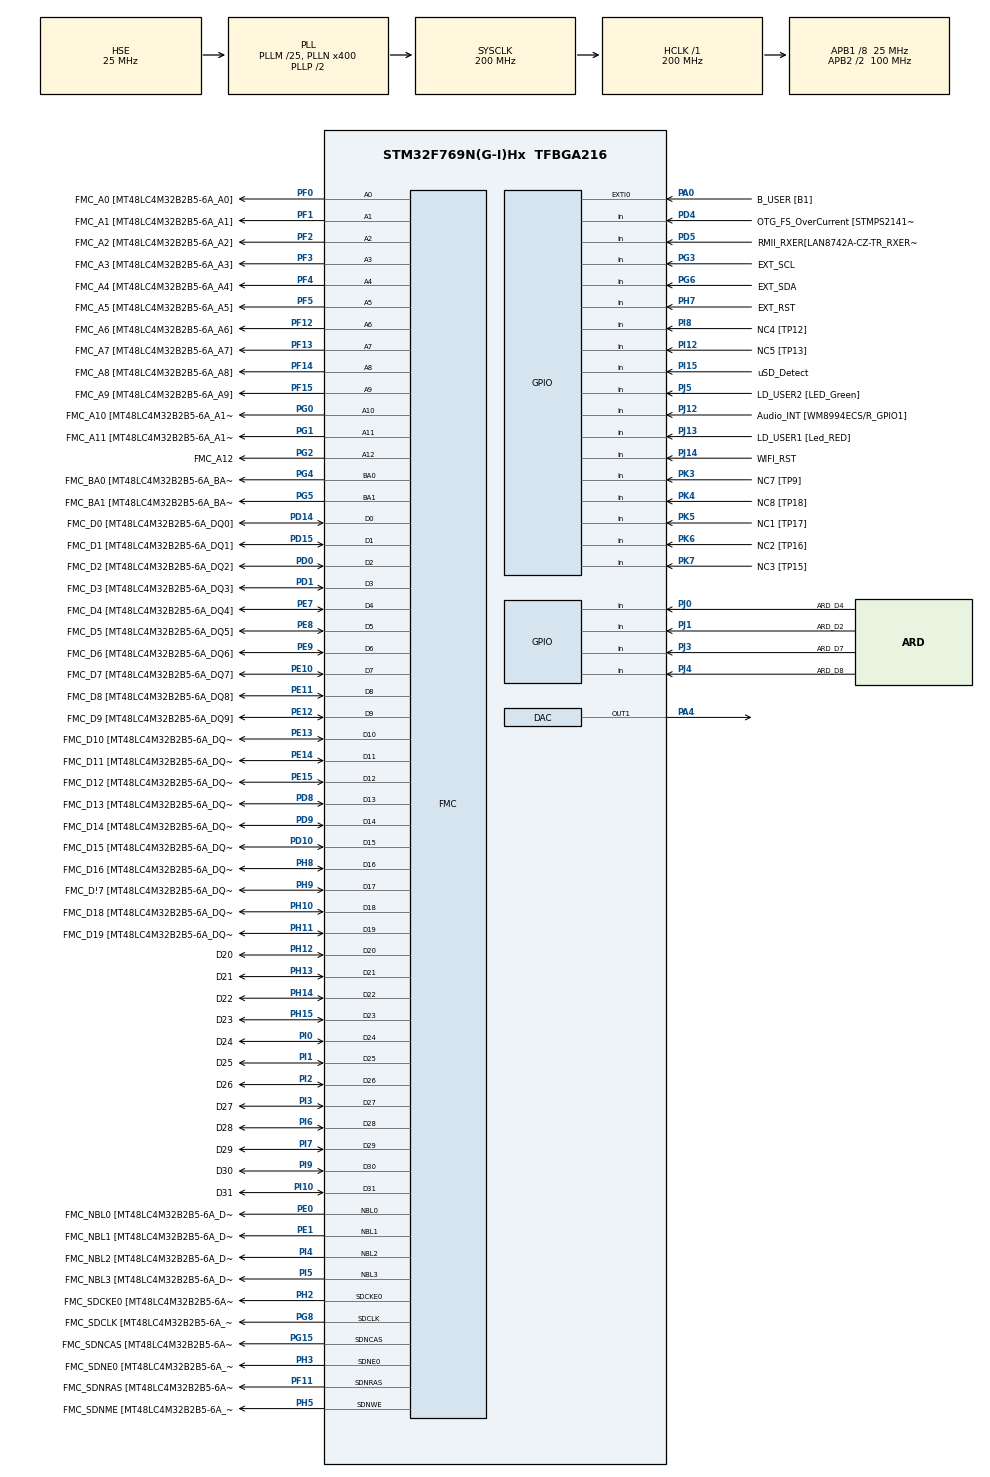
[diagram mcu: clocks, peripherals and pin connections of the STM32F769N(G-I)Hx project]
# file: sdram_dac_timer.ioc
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DAC.DAC_Channel=DAC_CHANNEL_1
DAC.DAC_OutputBuffer=DAC_OUTPUTBUFFER_ENABLE
DAC.DAC_Trigger=DAC_TRIGGER_T6_TRGO
DAC.WaveGeneration=DISABLE
Dma.DAC1.1.Direction=DMA_MEMORY_TO_PERIPH
Dma.DAC1.1.FIFOMode=DMA_FIFOMODE_DISABLE
Dma.DAC1.1.Instance=DMA1_Stream5
Dma.DAC1.1.MemDataAlignment=DMA_MDATAALIGN_HALFWORD
Dma.DAC1.1.MemInc=DMA_MINC_ENABLE
Dma.DAC1.1.Mode=DMA_CIRCULAR
Dma.DAC1.1.PeriphDataAlignment=DMA_PDATAALIGN_HALFWORD
Dma.DAC1.1.PeriphInc=DMA_PINC_DISABLE
Dma.DAC1.1.Priority=DMA_PRIORITY_LOW
Dma.MEMTOMEM.0.Direction=DMA_MEMORY_TO_MEMORY
Dma.MEMTOMEM.0.FIFOMode=DMA_FIFOMODE_ENABLE
Dma.MEMTOMEM.0.FIFOThreshold=DMA_FIFO_THRESHOLD_FULL
Dma.MEMTOMEM.0.Instance=DMA2_Stream0
Dma.MEMTOMEM.0.MemBurst=DMA_MBURST_SINGLE
Dma.MEMTOMEM.0.MemDataAlignment=DMA_MDATAALIGN_BYTE
Dma.MEMTOMEM.0.MemInc=DMA_MINC_ENABLE
Dma.MEMTOMEM.0.Mode=DMA_NORMAL
Dma.MEMTOMEM.0.PeriphBurst=DMA_PBURST_SINGLE
Dma.MEMTOMEM.0.PeriphDataAlignment=DMA_PDATAALIGN_BYTE
Dma.MEMTOMEM.0.PeriphInc=DMA_PINC_ENABLE
Dma.MEMTOMEM.0.Priority=DMA_PRIORITY_LOW
Dma.Request0=MEMTOMEM
Dma.Request1=DAC1
FMC.CASLatency1=FMC_SDRAM_CAS_LATENCY_2
FMC.ExitSelfRefreshDelay1=7
FMC.InternalBankNumber1=FMC_SDRAM_INTERN_BANKS_NUM_4
FMC.LoadToActiveDelay1=2
FMC.RCDDelay1=2
FMC.RPDelay1=2
FMC.RPDelay2=2
FMC.ReadBurst1=FMC_SDRAM_RBURST_ENABLE
FMC.ReadBurst2=FMC_SDRAM_RBURST_ENABLE
FMC.RowCycleDelay1=6
FMC.RowCycleDelay2=6
FMC.SDClockPeriod1=FMC_SDRAM_CLOCK_PERIOD_2
FMC.SDClockPeriod2=FMC_SDRAM_CLOCK_PERIOD_2
FMC.SDCoherentPinout1=MEMORY_PINOUT_OK
FMC.SDMemoryDataWidth1=FMC_SDRAM_MEM_BUS_WIDTH_32
FMC.SDRAM_Instance=FMC_SDRAM_DEVICE
FMC.SelfRefreshTime1=4
FMC.WriteRecoveryTime1=2
Mcu.Family=STM32F7
Mcu.Name=STM32F769N(G-I)Hx
Mcu.Package=TFBGA216
NVIC.DMA1_Stream5_IRQn=true\:0\:0\:false\:false\:true
NVIC.PriorityGroup=NVIC_PRIORITYGROUP_4
PA0/WKUP.GPIO_Label=B_USER [B1]
PA0/WKUP.Signal=GPXTI0
PA1.GPIO_Label=RMII_REF_CLK [LAN8742A-CZ-TR_REFCLK0]
PA1.Signal=ETH_REF_CLK
PA10.GPIO_Label=VCP_RX 
PA10.Signal=USART1_RX
PA11.GPIO_Label=SPI2_NSS
PA11.Signal=SPI2_NSS
PA12.GPIO_Label=ARD_D13/SCK
PA12.GPIO_Mode=GPIO_MODE_AF_PP
PA12.GPIO_PuPd=GPIO_NOPULL
PA12.GPIO_Speed=GPIO_SPEED_FREQ_LOW
PA12.Signal=SPI2_SCK
PA13.GPIO_Label=SWDIO
PA13.Signal=SYS_JTMS-SWDIO
PA14.GPIO_Label=SWCLK
PA14.Signal=SYS_JTCK-SWCLK
PA2.GPIO_Label=RMII_MDIO [LAN8742A-CZ-TR_MDIO]
PA2.Signal=ETH_MDIO
PA3.GPIO_Label=ULPI_D0 [USB3320C-EZK_D0]
PA3.Signal=USB_OTG_HS_ULPI_D0
PA4.Signal=COMP_DAC1_group
PA5.GPIO_Label=ULPI_CLK [USB3320C-EZK_CLKOUT]
PA5.Signal=USB_OTG_HS_ULPI_CK
PA6.GPIO_Label=ARD_A0
PA6.Signal=ADCx_IN6
PA7.GPIO_Label=RMII_CRS_DV [LAN8742A-CZ-TR_CRS_DV]
PA7.Signal=ETH_CRS_DV
PA9.GPIO_Label=VCP_TX [STM32F103CBT6_PA3]
PA9.GPIO_Mode=GPIO_MODE_AF_PP
PA9.GPIO_PuPd=GPIO_NOPULL
PA9.GPIO_Speed=GPIO_SPEED_FREQ_LOW
PA9.Signal=USART1_TX
PB0.GPIO_Label=ULPI_D1 [USB3320C-EZK_D1]
PB0.Signal=USB_OTG_HS_ULPI_D1
PB1.GPIO_Label=ULPI_D2 [USB3320C-EZK_D2]
PB1.Signal=USB_OTG_HS_ULPI_D2
PB10.GPIO_Label=ULPI_D3 [USB3320C-EZK_D3]
PB10.Signal=USB_OTG_HS_ULPI_D3
PB11.GPIO_Label=ULPI_D4 [USB3320C-EZK_D4]
PB11.Signal=USB_OTG_HS_ULPI_D4
PB12.GPIO_Label=ULPI_D5 [USB3320C-EZK_D5]
PB12.Signal=USB_OTG_HS_ULPI_D5
PB13.GPIO_Label=ULPI_D6 [USB3320C-EZK_D6]
PB13.Signal=USB_OTG_HS_ULPI_D6
PB14.GPIO_Label=ARDUINO MISO/D12
PB14.GPIO_Mode=GPIO_MODE_AF_PP
PB14.GPIO_PuPd=GPIO_NOPULL
PB14.GPIO_Speed=GPIO_SPEED_FREQ_LOW
PB14.Signal=SPI2_MISO
PB15.GPIO_Label=ARDUINO MOSI/PWM/D11
PB15.GPIO_Mode=GPIO_MODE_AF_PP
PB15.GPIO_PuPd=GPIO_NOPULL
PB15.GPIO_Speed=GPIO_SPEED_FREQ_LOW
PB15.Signal=SPI2_MOSI
PB2.GPIO_Label=QSPI_CLK
PB2.Signal=QUADSPI_CLK
PB3.GPIO_Label=uSD_D2
PB3.Signal=SDMMC2_D2
PB4.GPIO_Label=uSD_D3
PB4.Signal=SDMMC2_D3
PB5.GPIO_Label=ULPI_D7 [USB3320C-EZK_D7]
PB5.Signal=USB_OTG_HS_ULPI_D7
PB6.GPIO_Label=QSPI_NCS [N25Q128A13EF840E_S]
PB6.Signal=QUADSPI_BK1_NCS
PB7.GPIO_Label=AUDIO_SDA [WM8994ECS/R_SDA]
PB7.Signal=I2C4_SDA
PB8.GPIO_Label=ARDUINO SCL/D15
PB8.GPIO_Mode=GPIO_MODE_AF_OD
PB8.GPIO_PuPd=GPIO_NOPULL
PB8.GPIO_Speed=GPIO_SPEED_FREQ_LOW
PB8.Signal=I2C1_SCL
PB9.GPIO_Label=ARDUINO SDA/D14
PB9.GPIO_Mode=GPIO_MODE_AF_OD
PB9.GPIO_PuPd=GPIO_NOPULL
PB9.GPIO_Speed=GPIO_SPEED_FREQ_LOW
PB9.Signal=I2C1_SDA
PC0.GPIO_Label=ULPI_STP [USB3320C-EZK_STP]
PC0.Signal=USB_OTG_HS_ULPI_STP
PC1.GPIO_Label=RMII_MDC [LAN8742A-CZ-TR_MDC]
PC1.Signal=ETH_MDC
PC10.GPIO_Label=QSPI_D1 [MT25QL512ABB1EW9_DQ1]
PC10.Signal=QUADSPI_BK1_IO1
PC11.GPIO_Label=DFSDM_DATIN5 [TP100]
PC11.Signal=S_DATAIN5DFSDM1
PC12.GPIO_Label=WIFI_RX
PC12.Signal=UART5_TX
PC13.Signal=RTC_OUT_ALARM
PC14/OSC32_IN.GPIO_Label=RCC_OSC32_IN
PC14/OSC32_IN.Signal=RCC_OSC32_IN
PC15/OSC32_OUT.GPIO_Label=RCC_OSC32_OUT
PC15/OSC32_OUT.Signal=RCC_OSC32_OUT
PC2.GPIO_Label=ARD_A2
PC2.Signal=ADCx_IN12
PC3.GPIO_Label=DFSDM_DATIN1 [TP101]
PC3.Signal=S_DATAIN1DFSDM1
PC4.GPIO_Label=RMII_RXD0 [LAN8742A-CZ-TR_RXD0]
PC4.Signal=ETH_RXD0
PC5.GPIO_Label=RMII_RXD1 [LAN8742A-CZ-TR_RXD1]
PC5.Signal=ETH_RXD1
PC6.GPIO_Label=ARDUINO TX/D1
PC6.Signal=USART6_TX
PC7.GPIO_Label=ARD_D0/RX
PC7.Signal=USART6_RX
PC8.GPIO_Label=ARD_D5/PWM
PC8.Signal=S_TIM3_CH3
PC9.GPIO_Label=QSPI_D0 [N25Q128A13EF840E_DQ0]
PC9.Signal=QUADSPI_BK1_IO0
PD0.GPIO_Label=FMC_D2 [MT48LC4M32B2B5-6A_DQ2]
PD0.Signal=FMC_D2_DA2
PD1.GPIO_Label=FMC_D3 [MT48LC4M32B2B5-6A_DQ3]
PD1.Signal=FMC_D3_DA3
PD10.GPIO_Label=FMC_D15 [MT48LC4M32B2B5-6A_DQ15]
PD10.Signal=FMC_D15_DA15
PD11.GPIO_Label=SPDIF_TX [TP20]
PD11.Signal=SAI2_SD_A
PD12.GPIO_Label=AUDIO_SCL [WM8994ECS/R_SCLK]
PD12.Signal=I2C4_SCL
PD13.GPIO_Label=QSPI_D3 [N25Q128A13EF840E_DQ3]
PD13.Signal=QUADSPI_BK1_IO3
PD14.GPIO_Label=FMC_D0 [MT48LC4M32B2B5-6A_DQ0]
PD14.Signal=FMC_D0_DA0
PD15.GPIO_Label=FMC_D1 [MT48LC4M32B2B5-6A_DQ1]
PD15.Signal=FMC_D1_DA1
PD2.GPIO_Label=WIFI_TX
PD2.Signal=UART5_RX
PD3.GPIO_Label=DFSDM_CKOUT [TP102]
PD3.Signal=S_CKOUTDFSDM1
PD4.GPIO_Label=OTG_FS_OverCurrent [STMPS2141STR_Fault]
PD4.Signal=GPIO_Input
PD5.GPIO_Label=RMII_RXER[LAN8742A-CZ-TR_RXERR]
PD5.Signal=GPIO_Input
PD6.GPIO_Label=uSD_CLK
PD6.Signal=SDMMC2_CK
PD7.GPIO_Label=uSD_CMD
PD7.Signal=SDMMC2_CMD
PD8.GPIO_Label=FMC_D13 [MT48LC4M32B2B5-6A_DQ13]
PD8.Signal=FMC_D13_DA13
PD9.GPIO_Label=FMC_D14 [MT48LC4M32B2B5-6A_DQ14]
PD9.Signal=FMC_D14_DA14
PE0.GPIO_Label=FMC_NBL0 [MT48LC4M32B2B5-6A_DQM0]
PE0.Signal=FMC_NBL0
PE1.GPIO_Label=FMC_NBL1 [MT48LC4M32B2B5-6A_DQM1]
PE1.Signal=FMC_NBL1
PE10.GPIO_Label=FMC_D7 [MT48LC4M32B2B5-6A_DQ7]
PE10.Signal=FMC_D7_DA7
PE11.GPIO_Label=FMC_D8 [MT48LC4M32B2B5-6A_DQ8]
PE11.Signal=FMC_D8_DA8
PE12.GPIO_Label=FMC_D9 [MT48LC4M32B2B5-6A_DQ9]
PE12.Signal=FMC_D9_DA9
PE13.GPIO_Label=FMC_D10 [MT48LC4M32B2B5-6A_DQ10]
PE13.Signal=FMC_D10_DA10
PE14.GPIO_Label=FMC_D11 [MT48LC4M32B2B5-6A_DQ11]
PE14.Signal=FMC_D11_DA11
PE15.GPIO_Label=FMC_D12 [MT48LC4M32B2B5-6A_DQ12]
PE15.Signal=FMC_D12_DA12
PE2.GPIO_Label=QSPI_D2 [N25Q128A13EF840E_DQ2]
PE2.Signal=QUADSPI_BK1_IO2
PE3.GPIO_Label=SAI1_SDB [WM8994ECS/R_ADCDAT1]
PE3.Signal=SAI1_SD_B
PE4.GPIO_Label=SAI1_FSA [WM8994ECS/R_LRCLK1]
PE4.Signal=SAI1_FS_A
PE5.GPIO_Label=SAI1_SCKA [WM8994ECS/R_BCLK1]
PE5.Signal=SAI1_SCK_A
PE6.GPIO_Label=SAI1_SDA [WM8994ECS/R_DACDAT1]
PE6.Signal=SAI1_SD_A
PE7.GPIO_Label=FMC_D4 [MT48LC4M32B2B5-6A_DQ4]
PE7.Signal=FMC_D4_DA4
PE8.GPIO_Label=FMC_D5 [MT48LC4M32B2B5-6A_DQ5]
PE8.Signal=FMC_D5_DA5
PE9.GPIO_Label=FMC_D6 [MT48LC4M32B2B5-6A_DQ6]
PE9.Signal=FMC_D6_DA6
PF0.GPIO_Label=FMC_A0 [MT48LC4M32B2B5-6A_A0]
PF0.Signal=FMC_A0
PF1.GPIO_Label=FMC_A1 [MT48LC4M32B2B5-6A_A1]
PF1.Signal=FMC_A1
PF10.GPIO_Label=ARDUINO A1
PF10.GPIO_Mode=GPIO_MODE_ANALOG
PF10.GPIO_PuPd=GPIO_NOPULL
PF10.Signal=ADC3_IN8
PF11.GPIO_Label=FMC_SDNRAS [MT48LC4M32B2B5-6A_RAS]
PF11.Signal=FMC_SDNRAS
PF12.GPIO_Label=FMC_A6 [MT48LC4M32B2B5-6A_A6]
PF12.Signal=FMC_A6
PF13.GPIO_Label=FMC_A7 [MT48LC4M32B2B5-6A_A7]
PF13.Signal=FMC_A7
PF14.GPIO_Label=FMC_A8 [MT48LC4M32B2B5-6A_A8]
PF14.Signal=FMC_A8
PF15.GPIO_Label=FMC_A9 [MT48LC4M32B2B5-6A_A9]
PF15.Signal=FMC_A9
PF2.GPIO_Label=FMC_A2 [MT48LC4M32B2B5-6A_A2]
PF2.Signal=FMC_A2
PF3.GPIO_Label=FMC_A3 [MT48LC4M32B2B5-6A_A3]
PF3.Signal=FMC_A3
PF4.GPIO_Label=FMC_A4 [MT48LC4M32B2B5-6A_A4]
PF4.Signal=FMC_A4
PF5.GPIO_Label=FMC_A5 [MT48LC4M32B2B5-6A_A5]
PF5.Signal=FMC_A5
PF6.GPIO_Label=ARD_D3/PWM
PF6.Signal=S_TIM10_CH1
PF7.GPIO_Label=ARD_D6/PWM
PF7.Signal=S_TIM11_CH1
PF8.GPIO_Label=ARDUINO A3
PF8.GPIO_Mode=GPIO_MODE_ANALOG
PF8.GPIO_PuPd=GPIO_NOPULL
PF8.Signal=ADC3_IN6
PF9.GPIO_Label=ARDUINO A2
PF9.GPIO_Mode=GPIO_MODE_ANALOG
PF9.GPIO_PuPd=GPIO_NOPULL
PF9.Signal=ADC3_IN7
PG0.GPIO_Label=FMC_A10 [MT48LC4M32B2B5-6A_A10]
PG0.Signal=FMC_A10
PG1.GPIO_Label=FMC_A11 [MT48LC4M32B2B5-6A_A11]
PG1.Signal=FMC_A11
PG10.GPIO_Label=uSD_D1
PG10.Signal=SDMMC2_D1
PG11.GPIO_Label=RMII_TX_EN [LAN8742A-CZ-TR_TXEN]
PG11.Signal=ETH_TX_EN
PG12.GPIO_Label=SPDIF_RX [74LVC1G04SE_4]
PG12.Signal=SPDIFRX_IN1
PG13.GPIO_Label=RMII_TXD0 [LAN8742A-CZ-TR_TXD0]
PG13.Signal=ETH_TXD0
PG14.GPIO_Label=RMII_TXD1 [LAN8742A-CZ-TR_TXD1]
PG14.Signal=ETH_TXD1
PG15.GPIO_Label=FMC_SDNCAS [MT48LC4M32B2B5-6A_CAS]
PG15.Signal=FMC_SDNCAS
PG2.GPIO_Label=FMC_A12
PG2.Signal=FMC_A12
PG3.GPIO_Label=EXT_SCL
PG3.Signal=GPIO_Input
PG4.GPIO_Label=FMC_BA0 [MT48LC4M32B2B5-6A_BA0]
PG4.Signal=FMC_A14_BA0
PG5.GPIO_Label=FMC_BA1 [MT48LC4M32B2B5-6A_BA1]
PG5.Signal=FMC_A15_BA1
PG6.GPIO_Label=EXT_SDA
PG6.Signal=GPIO_Input
PG7.GPIO_Label=SAI1_MCLKA [WM8994ECS/R_MCLK1]
PG7.Signal=SAI1_MCLK_A
PG8.GPIO_Label=FMC_SDCLK [MT48LC4M32B2B5-6A_CLK]
PG8.Signal=FMC_SDCLK
PG9.GPIO_Label=uSD_D0
PG9.Signal=SDMMC2_D0
PH0/OSC_IN.GPIO_Label=OSC_25M [NZ2520SB-25.00M_OUT]
PH0/OSC_IN.Mode=HSE-External-Clock-Source
PH0/OSC_IN.Signal=RCC_OSC_IN
PH1/OSC_OUT.Mode=HSE-External-Clock-Source
PH1/OSC_OUT.Signal=RCC_OSC_OUT
PH10.GPIO_Label=FMC_D18 [MT48LC4M32B2B5-6A_DQ18]
PH10.Signal=FMC_D18
PH11.GPIO_Label=FMC_D19 [MT48LC4M32B2B5-6A_DQ19]
PH11.Signal=FMC_D19
PH12.GPIO_Label=D20
PH12.Signal=FMC_D20
PH13.GPIO_Label=D21
PH13.Signal=FMC_D21
PH14.GPIO_Label=D22
PH14.Signal=FMC_D22
PH15.GPIO_Label=D23
PH15.Signal=FMC_D23
PH2.GPIO_Label=FMC_SDCKE0 [MT48LC4M32B2B5-6A_CKE]
PH2.Mode=SdramChipSelect1_1
PH2.Signal=FMC_SDCKE0
PH3.GPIO_Label=FMC_SDNE0 [MT48LC4M32B2B5-6A_CS]
PH3.Mode=SdramChipSelect1_1
PH3.Signal=FMC_SDNE0
PH4.GPIO_Label=ULPI_NXT [USB3320C-EZK_NXT]
PH4.Signal=USB_OTG_HS_ULPI_NXT
PH5.GPIO_Label=FMC_SDNME [MT48LC4M32B2B5-6A_WE]
PH5.Signal=FMC_SDNWE
PH6.GPIO_Label=ARDUINO PWM/D6
PH6.Signal=S_TIM12_CH1
PH7.GPIO_Label=EXT_RST
PH7.Signal=GPIO_Input
PH8.GPIO_Label=FMC_D16 [MT48LC4M32B2B5-6A_DQ16]
PH8.Signal=FMC_D16
PH9.GPIO_Label=FMC_D\!7 [MT48LC4M32B2B5-6A_DQ17]
PH9.Signal=FMC_D17
PI0.GPIO_Label=D24
PI0.Signal=FMC_D24
PI1.GPIO_Label=D25
PI1.Signal=FMC_D25
PI10.GPIO_Label=D31
PI10.Signal=FMC_D31
PI11.GPIO_Label=ULPI_DIR [USB3320C-EZK_DIR]
PI11.Signal=USB_OTG_HS_ULPI_DIR
PI12.GPIO_Label=NC5 [TP13]
PI12.Signal=GPIO_Input
PI15.GPIO_Label=uSD_Detect
PI15.Signal=GPIO_Input
PI2.GPIO_Label=D26
PI2.Signal=FMC_D26
PI3.GPIO_Label=D27
PI3.Signal=FMC_D27
PI4.GPIO_Label=FMC_NBL2 [MT48LC4M32B2B5-6A_DQM2]
PI4.Signal=FMC_NBL2
PI5.GPIO_Label=FMC_NBL3 [MT48LC4M32B2B5-6A_DQM3]
PI5.Signal=FMC_NBL3
PI6.GPIO_Label=D28
PI6.Signal=FMC_D28
PI7.GPIO_Label=D29
PI7.Signal=FMC_D29
PI8.GPIO_Label=NC4 [TP12]
PI8.Signal=GPIO_Input
PI9.GPIO_Label=D30
PI9.Signal=FMC_D30
PJ0.GPIO_Label=ARD_D4
PJ0.Signal=GPIO_Input
PJ1.GPIO_Label=ARD_D2
PJ1.Signal=GPIO_Input
PJ12.GPIO_Label=Audio_INT [WM8994ECS/R_GPIO1]
PJ12.Signal=GPIO_Input
PJ13.GPIO_Label=LD_USER1 [Led_RED]
PJ13.Signal=GPIO_Input
PJ14.GPIO_Label=WIFI_RST
PJ14.Signal=GPIO_Input
PJ3.GPIO_Label=ARD_D7
PJ3.Signal=GPIO_Input
PJ4.GPIO_Label=ARD_D8
PJ4.Signal=GPIO_Input
PJ5.GPIO_Label=LD_USER2 [LED_Green]
PJ5.Signal=GPIO_Input
PK3.GPIO_Label=NC7 [TP9]
PK3.Signal=GPIO_Input
PK4.GPIO_Label=NC8 [TP18]
PK4.Signal=GPIO_Input
PK5.GPIO_Label=NC1 [TP17]
PK5.Signal=GPIO_Input
PK6.GPIO_Label=NC2 [TP16]
PK6.Signal=GPIO_Input
PK7.GPIO_Label=NC3 [TP15]
PK7.Signal=GPIO_Input
ProjectManager.HeapSize=0x200
ProjectManager.StackSize=0x400
ProjectManager.TargetToolchain=MDK-ARM V5
RCC.AHBCLKDivider=RCC_SYSCLK_DIV1
RCC.AHBFreq_Value=200000000
RCC.APB1CLKDivider=RCC_HCLK_DIV8
RCC.APB1Freq_Value=25000000
RCC.APB1TimFreq_Value=50000000
RCC.APB2CLKDivider=RCC_HCLK_DIV2
RCC.APB2Freq_Value=100000000
RCC.APB2TimFreq_Value=200000000
RCC.CECEnable=false
RCC.ClockTypeHCLK=RCC_CLOCKTYPE_HCLK
RCC.ClockTypePCLK1=RCC_CLOCKTYPE_PCLK1
RCC.ClockTypePCLK2=RCC_CLOCKTYPE_PCLK2
RCC.ClockTypeSysClk=RCC_CLOCKTYPE_SYSCLK
RCC.CortexFreq_Value=200000000
RCC.EnableHSE=true
RCC.EnableHSERTCDevisor=false
RCC.EnableLSE=false
RCC.EnableLSERTC=false
RCC.EnbaleCSS=false
RCC.ExtClockEnable=false
RCC.HCLKFreq_Value=200000000
RCC.HSEState=RCC_HSE_BYPASS
RCC.HSE_VALUE=25000000
RCC.HSIState=RCC_HSI_ON
RCC.HSI_VALUE=16000000
RCC.I2C1Enable=false
RCC.I2C2Enable=false
RCC.I2C3Enable=false
RCC.I2C4Enable=false
RCC.I2SEnable=false
RCC.LCDEnable=false
RCC.LPTIM1Enable=false
RCC.LSE_VALUE=32768
RCC.LSIState=RCC_LSI_OFF
RCC.MCO1OutPutEnable=false
RCC.MCO2I2SEnable=false
RCC.MCO2OutPutEnable=false
RCC.OscillatorTypeHSE=RCC_OSCILLATORTYPE_HSE
RCC.OscillatorTypeHSI=RCC_OSCILLATORTYPE_HSI
RCC.PLLM=25
RCC.PLLN=400
RCC.PLLP=RCC_PLLP_DIV2
RCC.PLLQ=4
RCC.PLLSAIQ=3
RCC.PLLSourceVirtual=RCC_PLLSOURCE_HSE
RCC.PLLState=RCC_PLL_ON
RCC.RTCEnable=false
RCC.SAI1Enable=false
RCC.SAI2Enable=false
RCC.SDMMC1Enable=false
RCC.SPDIFEnable=false
RCC.SYSCLKFreq_VALUE=200000000
RCC.SYSCLKSource=RCC_SYSCLKSOURCE_PLLCLK
RCC.UART4Enable=false
RCC.UART5Enable=false
RCC.UART7Enable=false
RCC.UART8Enable=false
RCC.USART1Enable=false
RCC.USART2Enable=false
RCC.USART3Enable=false
RCC.USART6Enable=false
RCC.USBEnable=false
RCC.USBFreq_Value=100000000
RCC.VCOOutputFreq_Value=400000000
SH.ADCx_IN12.0=ADC1_IN12
SH.ADCx_IN6.0=ADC1_IN6
SH.COMP_DAC1_group.0=DAC_OUT1,DAC_OUT1
SH.FMC_A0.0=FMC_A0,13b-sda1
SH.FMC_A1.0=FMC_A1,13b-sda1
SH.FMC_A10.0=FMC_A10,13b-sda1
SH.FMC_A11.0=FMC_A11,13b-sda1
SH.FMC_A12.0=FMC_A12,13b-sda1
SH.FMC_A14_BA0.0=FMC_BA0,FourSdramBanks1
SH.FMC_A15_BA1.0=FMC_BA1,FourSdramBanks1
SH.FMC_A2.0=FMC_A2,13b-sda1
SH.FMC_A3.0=FMC_A3,13b-sda1
SH.FMC_A4.0=FMC_A4,13b-sda1
SH.FMC_A5.0=FMC_A5,13b-sda1
SH.FMC_A6.0=FMC_A6,13b-sda1
SH.FMC_A7.0=FMC_A7,13b-sda1
SH.FMC_A8.0=FMC_A8,13b-sda1
SH.FMC_A9.0=FMC_A9,13b-sda1
SH.FMC_D0_DA0.0=FMC_D0,sd-32b-d1
SH.FMC_D10_DA10.0=FMC_D10,sd-32b-d1
SH.FMC_D11_DA11.0=FMC_D11,sd-32b-d1
SH.FMC_D12_DA12.0=FMC_D12,sd-32b-d1
SH.FMC_D13_DA13.0=FMC_D13,sd-32b-d1
SH.FMC_D14_DA14.0=FMC_D14,sd-32b-d1
SH.FMC_D15_DA15.0=FMC_D15,sd-32b-d1
SH.FMC_D16.0=FMC_D16,sd-32b-d1
SH.FMC_D17.0=FMC_D17,sd-32b-d1
SH.FMC_D18.0=FMC_D18,sd-32b-d1
SH.FMC_D19.0=FMC_D19,sd-32b-d1
SH.FMC_D1_DA1.0=FMC_D1,sd-32b-d1
SH.FMC_D20.0=FMC_D20,sd-32b-d1
SH.FMC_D21.0=FMC_D21,sd-32b-d1
SH.FMC_D22.0=FMC_D22,sd-32b-d1
SH.FMC_D23.0=FMC_D23,sd-32b-d1
SH.FMC_D24.0=FMC_D24,sd-32b-d1
SH.FMC_D25.0=FMC_D25,sd-32b-d1
SH.FMC_D26.0=FMC_D26,sd-32b-d1
SH.FMC_D27.0=FMC_D27,sd-32b-d1
SH.FMC_D28.0=FMC_D28,sd-32b-d1
SH.FMC_D29.0=FMC_D29,sd-32b-d1
SH.FMC_D2_DA2.0=FMC_D2,sd-32b-d1
SH.FMC_D30.0=FMC_D30,sd-32b-d1
SH.FMC_D31.0=FMC_D31,sd-32b-d1
SH.FMC_D3_DA3.0=FMC_D3,sd-32b-d1
SH.FMC_D4_DA4.0=FMC_D4,sd-32b-d1
SH.FMC_D5_DA5.0=FMC_D5,sd-32b-d1
SH.FMC_D6_DA6.0=FMC_D6,sd-32b-d1
SH.FMC_D7_DA7.0=FMC_D7,sd-32b-d1
SH.FMC_D8_DA8.0=FMC_D8,sd-32b-d1
SH.FMC_D9_DA9.0=FMC_D9,sd-32b-d1
SH.FMC_NBL0.0=FMC_NBL0,Sd4ByteEnable1
SH.FMC_NBL1.0=FMC_NBL1,Sd4ByteEnable1
SH.FMC_NBL2.0=FMC_NBL2,Sd4ByteEnable1
SH.FMC_NBL3.0=FMC_NBL3,Sd4ByteEnable1
SH.FMC_SDCLK.0=FMC_SDCLK,13b-sda1
SH.FMC_SDNCAS.0=FMC_SDNCAS,13b-sda1
SH.FMC_SDNRAS.0=FMC_SDNRAS,13b-sda1
SH.FMC_SDNWE.0=FMC_SDNWE,13b-sda1
SH.S_CKOUTDFSDM1.0=DFSDM1_CKOUT
SH.S_DATAIN1DFSDM1.0=DFSDM1_DATIN1
SH.S_DATAIN5DFSDM1.0=DFSDM1_DATIN5
SH.S_TIM10_CH1.0=TIM10_CH1
SH.S_TIM11_CH1.0=TIM11_CH1
SH.S_TIM12_CH1.0=TIM12_CH1
SH.S_TIM3_CH3.0=TIM3_CH3
TIM6.AutoReloadPreload=TIM_AUTORELOAD_PRELOAD_DISABLE
TIM6.Period=32768
TIM6.TIM_MasterOutputTrigger=TIM_TRGO_UPDATE
TIM6.TIM_MasterSlaveMode=TIM_MASTERSLAVEMODE_DISABLE
VP_TIM6_VS_ClockSourceINT.Mode=Enable_Timer
board=STM32F769I-DISC1

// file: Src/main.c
/**
  ******************************************************************************
  * File Name          : main.c
  * Description        : Main program body
  ******************************************************************************
  *
  * COPYRIGHT(c) 2017 STMicroelectronics
  *
  * Redistribution and use in source and binary forms, with or without modification,
  * are permitted provided that the following conditions are met:
  *   1. Redistributions of source code must retain the above copyright notice,
  *      this list of conditions and the following disclaimer.
  *   2. Redistributions in binary form must reproduce the above copyright notice,
  *      this list of conditions and the following disclaimer in the documentation
  *      and/or other materials provided with the distribution.
  *   3. Neither the name of STMicroelectronics nor the names of its contributors
  *      may be used to endorse or promote products derived from this software
  *      without specific prior written permission.
  *
  * THIS SOFTWARE IS PROVIDED BY THE COPYRIGHT HOLDERS AND CONTRIBUTORS "AS IS"
  * AND ANY EXPRESS OR IMPLIED WARRANTIES, INCLUDING, BUT NOT LIMITED TO, THE
  * IMPLIED WARRANTIES OF MERCHANTABILITY AND FITNESS FOR A PARTICULAR PURPOSE ARE
  * DISCLAIMED. IN NO EVENT SHALL THE COPYRIGHT HOLDER OR CONTRIBUTORS BE LIABLE
  * FOR ANY DIRECT, INDIRECT, INCIDENTAL, SPECIAL, EXEMPLARY, OR CONSEQUENTIAL
  * DAMAGES (INCLUDING, BUT NOT LIMITED TO, PROCUREMENT OF SUBSTITUTE GOODS OR
  * SERVICES; LOSS OF USE, DATA, OR PROFITS; OR BUSINESS INTERRUPTION) HOWEVER
  * CAUSED AND ON ANY THEORY OF LIABILITY, WHETHER IN CONTRACT, STRICT LIABILITY,
  * OR TORT (INCLUDING NEGLIGENCE OR OTHERWISE) ARISING IN ANY WAY OUT OF THE USE
  * OF THIS SOFTWARE, EVEN IF ADVISED OF THE POSSIBILITY OF SUCH DAMAGE.
  *
  ******************************************************************************
  */
#include "main.h"
#include "stm32f7xx_hal.h"

DAC_HandleTypeDef hdac;
DMA_HandleTypeDef hdma_dac1;

TIM_HandleTypeDef htim6;

DMA_HandleTypeDef hdma_memtomem_dma2_stream0;
SDRAM_HandleTypeDef hsdram1;

/* USER CODE BEGIN PV */
/* Private variables ---------------------------------------------------------*/
const uint16_t sine_wave_array[32] = {2047, 1648, 1264, 910, 600,  345,
                    156, 39,  0,  39,  156,  345,
                    600, 910, 1264, 1648, 2048, 2447,
                    2831, 3185, 3495, 3750, 3939, 4056,
                    4095, 4056, 3939, 3750, 3495, 3185,
                    2831, 2447};
/* USER CODE END PV */

void SystemClock_Config(void);
void Error_Handler(void);
static void MX_GPIO_Init(void);
static void MX_DMA_Init(void);
static void MX_DAC_Init(void);
static void MX_FMC_Init(void);
static void MX_TIM6_Init(void);

/* USER CODE BEGIN PFP */
/* Private function prototypes -----------------------------------------------*/

/* USER CODE END PFP */

int main(void)
{

  /* MCU Configuration----------------------------------------------------------*/

  /* Reset of all peripherals, Initializes the Flash interface and the Systick. */
  HAL_Init();

  /* Configure the system clock */
  SystemClock_Config();

  /* Initialize all configured peripherals */
  MX_GPIO_Init();
  MX_DMA_Init();
  MX_DAC_Init();
  MX_FMC_Init();
  MX_TIM6_Init();

  /* USER CODE BEGIN 2 */
	HAL_TIM_Base_Start(&htim6);
	HAL_DAC_Start(&hdac, DAC_CHANNEL_1);
	HAL_DAC_Start_DMA(&hdac, DAC_CHANNEL_1, (uint32_t*)sine_wave_array, 32, DAC_ALIGN_12B_R);
  /* USER CODE END 2 */

  /* Infinite loop */
  while (1)
  {

  }

}

/** System Clock Configuration
*/
void SystemClock_Config(void)
{

  RCC_OscInitTypeDef RCC_OscInitStruct;
  RCC_ClkInitTypeDef RCC_ClkInitStruct;

    /**Configure the main internal regulator output voltage
    */
  __HAL_RCC_PWR_CLK_ENABLE();

  __HAL_PWR_VOLTAGESCALING_CONFIG(PWR_REGULATOR_VOLTAGE_SCALE1);

    /**Initializes the CPU, AHB and APB busses clocks
    */
  RCC_OscInitStruct.OscillatorType = RCC_OSCILLATORTYPE_HSI|RCC_OSCILLATORTYPE_HSE;
  RCC_OscInitStruct.HSEState = RCC_HSE_BYPASS;
	RCC_OscInitStruct.HSIState = RCC_HSI_ON;
  RCC_OscInitStruct.PLL.PLLState = RCC_PLL_ON;
  RCC_OscInitStruct.PLL.PLLSource = RCC_PLLSOURCE_HSE;
  RCC_OscInitStruct.PLL.PLLM = 25;
  RCC_OscInitStruct.PLL.PLLN = 400;
  RCC_OscInitStruct.PLL.PLLP = RCC_PLLP_DIV2;
  RCC_OscInitStruct.PLL.PLLQ = 4;
  if (HAL_RCC_OscConfig(&RCC_OscInitStruct) != HAL_OK)
  {
    Error_Handler();
  }

    /**Activate the Over-Drive mode
    */
  if (HAL_PWREx_EnableOverDrive() != HAL_OK)
  {
    Error_Handler();
  }

    /**Initializes the CPU, AHB and APB busses clocks
    */
  RCC_ClkInitStruct.ClockType = RCC_CLOCKTYPE_HCLK|RCC_CLOCKTYPE_SYSCLK
                              |RCC_CLOCKTYPE_PCLK1|RCC_CLOCKTYPE_PCLK2;
  RCC_ClkInitStruct.SYSCLKSource = RCC_SYSCLKSOURCE_PLLCLK;
  RCC_ClkInitStruct.AHBCLKDivider = RCC_SYSCLK_DIV1;
  RCC_ClkInitStruct.APB1CLKDivider = RCC_HCLK_DIV8;
  RCC_ClkInitStruct.APB2CLKDivider = RCC_HCLK_DIV2;

  if (HAL_RCC_ClockConfig(&RCC_ClkInitStruct, FLASH_LATENCY_6) != HAL_OK)
  {
    Error_Handler();
  }

    /**Configure the Systick interrupt time
    */
  HAL_SYSTICK_Config(HAL_RCC_GetHCLKFreq()/1000);

    /**Configure the Systick
    */
  HAL_SYSTICK_CLKSourceConfig(SYSTICK_CLKSOURCE_HCLK);

  /* SysTick_IRQn interrupt configuration */
  HAL_NVIC_SetPriority(SysTick_IRQn, 0, 0);
}

/* DAC init function */
static void MX_DAC_Init(void)
{

  DAC_ChannelConfTypeDef sConfig;

    /**DAC Initialization
    */
  hdac.Instance = DAC;
  if (HAL_DAC_Init(&hdac) != HAL_OK)
  {
    Error_Handler();
  }

    /**DAC channel OUT1 config
    */
  sConfig.DAC_Trigger = DAC_TRIGGER_T6_TRGO;
  sConfig.DAC_OutputBuffer = DAC_OUTPUTBUFFER_ENABLE;
  if (HAL_DAC_ConfigChannel(&hdac, &sConfig, DAC_CHANNEL_1) != HAL_OK)
  {
    Error_Handler();
  }

}

/* TIM6 init function */
static void MX_TIM6_Init(void)
{

  TIM_MasterConfigTypeDef sMasterConfig;

  htim6.Instance = TIM6;
  htim6.Init.Prescaler = 0;
  htim6.Init.CounterMode = TIM_COUNTERMODE_UP;
  htim6.Init.Period = 32768;
  htim6.Init.AutoReloadPreload = TIM_AUTORELOAD_PRELOAD_DISABLE;
  if (HAL_TIM_Base_Init(&htim6) != HAL_OK)
  {
    Error_Handler();
  }

  sMasterConfig.MasterOutputTrigger = TIM_TRGO_UPDATE;
  sMasterConfig.MasterSlaveMode = TIM_MASTERSLAVEMODE_DISABLE;
  if (HAL_TIMEx_MasterConfigSynchronization(&htim6, &sMasterConfig) != HAL_OK)
  {
    Error_Handler();
  }

}

static void MX_DMA_Init(void)
{
  /* DMA controller clock enable */
  __HAL_RCC_DMA2_CLK_ENABLE();
  __HAL_RCC_DMA1_CLK_ENABLE();

  /* Configure DMA request hdma_memtomem_dma2_stream0 on DMA2_Stream0 */
  hdma_memtomem_dma2_stream0.Instance = DMA2_Stream0;
  hdma_memtomem_dma2_stream0.Init.Channel = DMA_CHANNEL_0;
  hdma_memtomem_dma2_stream0.Init.Direction = DMA_MEMORY_TO_MEMORY;
  hdma_memtomem_dma2_stream0.Init.PeriphInc = DMA_PINC_ENABLE;
  hdma_memtomem_dma2_stream0.Init.MemInc = DMA_MINC_ENABLE;
  hdma_memtomem_dma2_stream0.Init.PeriphDataAlignment = DMA_PDATAALIGN_BYTE;
  hdma_memtomem_dma2_stream0.Init.MemDataAlignment = DMA_MDATAALIGN_BYTE;
  hdma_memtomem_dma2_stream0.Init.Mode = DMA_NORMAL;
  hdma_memtomem_dma2_stream0.Init.Priority = DMA_PRIORITY_LOW;
  hdma_memtomem_dma2_stream0.Init.FIFOMode = DMA_FIFOMODE_ENABLE;
  hdma_memtomem_dma2_stream0.Init.FIFOThreshold = DMA_FIFO_THRESHOLD_FULL;
  hdma_memtomem_dma2_stream0.Init.MemBurst = DMA_MBURST_SINGLE;
  hdma_memtomem_dma2_stream0.Init.PeriphBurst = DMA_PBURST_SINGLE;
  if (HAL_DMA_Init(&hdma_memtomem_dma2_stream0) != HAL_OK)
  {
    Error_Handler();
  }

  /* DMA interrupt init */
  /* DMA1_Stream5_IRQn interrupt configuration */
  HAL_NVIC_SetPriority(DMA1_Stream5_IRQn, 0, 0);
  HAL_NVIC_EnableIRQ(DMA1_Stream5_IRQn);

}
/* FMC initialization function */
static void MX_FMC_Init(void)
{
  FMC_SDRAM_TimingTypeDef SdramTiming;

  /** Perform the SDRAM1 memory initialization sequence
  */
  hsdram1.Instance = FMC_SDRAM_DEVICE;
  /* hsdram1.Init */
  hsdram1.Init.SDBank = FMC_SDRAM_BANK1;
  hsdram1.Init.ColumnBitsNumber = FMC_SDRAM_COLUMN_BITS_NUM_8;
  hsdram1.Init.RowBitsNumber = FMC_SDRAM_ROW_BITS_NUM_13;
  hsdram1.Init.MemoryDataWidth = FMC_SDRAM_MEM_BUS_WIDTH_32;
  hsdram1.Init.InternalBankNumber = FMC_SDRAM_INTERN_BANKS_NUM_4;
  hsdram1.Init.CASLatency = FMC_SDRAM_CAS_LATENCY_2;
  hsdram1.Init.WriteProtection = FMC_SDRAM_WRITE_PROTECTION_DISABLE;
  hsdram1.Init.SDClockPeriod = FMC_SDRAM_CLOCK_PERIOD_2;
  hsdram1.Init.ReadBurst = FMC_SDRAM_RBURST_ENABLE;
  hsdram1.Init.ReadPipeDelay = FMC_SDRAM_RPIPE_DELAY_0;
  /* SdramTiming */
  SdramTiming.LoadToActiveDelay = 2;
  SdramTiming.ExitSelfRefreshDelay = 7;
  SdramTiming.SelfRefreshTime = 4;
  SdramTiming.RowCycleDelay = 6;
  SdramTiming.WriteRecoveryTime = 2;
  SdramTiming.RPDelay = 2;
  SdramTiming.RCDDelay = 2;

  if (HAL_SDRAM_Init(&hsdram1, &SdramTiming) != HAL_OK)
  {
    Error_Handler();
  }

}

/** Configure pins
     PE4   ------> SAI1_FS_A
     PE3   ------> SAI1_SD_B
     PE2   ------> QUADSPI_BK1_IO2
     PG14   ------> ETH_TXD1
     PB8   ------> I2C1_SCL
     PB5   ------> USB_OTG_HS_ULPI_D7
     PB4   ------> SDMMC2_D3
     PB3   ------> SDMMC2_D2
     PD7   ------> SDMMC2_CMD
     PC12   ------> UART5_TX
     PE5   ------> SAI1_SCK_A
     PE6   ------> SAI1_SD_A
     PG13   ------> ETH_TXD0
     PB9   ------> I2C1_SDA
     PB7   ------> I2C4_SDA
     PB6   ------> QUADSPI_BK1_NCS
     PG11   ------> ETH_TX_EN
     PD6   ------> SDMMC2_CK
     PC11   ------> S_DATAIN5DFSDM1
     PC10   ------> QUADSPI_BK1_IO1
     PA12   ------> SPI2_SCK
     PG12   ------> SPDIFRX_IN1
     PG10   ------> SDMMC2_D1
     PD3   ------> S_CKOUTDFSDM1
     PA11   ------> SPI2_NSS
     PG9   ------> SDMMC2_D0
     PD2   ------> UART5_RX
     PA10   ------> USART1_RX
     PA9   ------> USART1_TX
     PI11   ------> USB_OTG_HS_ULPI_DIR
     PC9   ------> QUADSPI_BK1_IO0
     PC8   ------> S_TIM3_CH3
     PC7   ------> USART6_RX
     PH4   ------> USB_OTG_HS_ULPI_NXT
     PC6   ------> USART6_TX
     PG7   ------> SAI1_MCLK_A
     PF7   ------> S_TIM11_CH1
     PF6   ------> S_TIM10_CH1
     PB13   ------> USB_OTG_HS_ULPI_D6
     PF10   ------> ADC3_IN8
     PF9   ------> ADC3_IN7
     PF8   ------> ADC3_IN6
     PC3   ------> S_DATAIN1DFSDM1
     PB12   ------> USB_OTG_HS_ULPI_D5
     PC0   ------> USB_OTG_HS_ULPI_STP
     PC1   ------> ETH_MDC
     PC2   ------> ADCx_IN12
     PB2   ------> QUADSPI_CLK
     PD12   ------> I2C4_SCL
     PD13   ------> QUADSPI_BK1_IO3
     PA1   ------> ETH_REF_CLK
     PC4   ------> ETH_RXD0
     PD11   ------> SAI2_SD_A
     PA2   ------> ETH_MDIO
     PA6   ------> ADCx_IN6
     PA5   ------> USB_OTG_HS_ULPI_CK
     PC5   ------> ETH_RXD1
     PB10   ------> USB_OTG_HS_ULPI_D3
     PH6   ------> S_TIM12_CH1
     PA3   ------> USB_OTG_HS_ULPI_D0
     PA7   ------> ETH_CRS_DV
     PB1   ------> USB_OTG_HS_ULPI_D2
     PB0   ------> USB_OTG_HS_ULPI_D1
     PB11   ------> USB_OTG_HS_ULPI_D4
     PB14   ------> SPI2_MISO
     PB15   ------> SPI2_MOSI
*/
static void MX_GPIO_Init(void)
{

  GPIO_InitTypeDef GPIO_InitStruct;

  /* GPIO Ports Clock Enable */
  __HAL_RCC_GPIOE_CLK_ENABLE();
  __HAL_RCC_GPIOG_CLK_ENABLE();
  __HAL_RCC_GPIOB_CLK_ENABLE();
  __HAL_RCC_GPIOD_CLK_ENABLE();
  __HAL_RCC_GPIOC_CLK_ENABLE();
  __HAL_RCC_GPIOA_CLK_ENABLE();
  __HAL_RCC_GPIOJ_CLK_ENABLE();
  __HAL_RCC_GPIOI_CLK_ENABLE();
  __HAL_RCC_GPIOK_CLK_ENABLE();
  __HAL_RCC_GPIOF_CLK_ENABLE();
  __HAL_RCC_GPIOH_CLK_ENABLE();

  /*Configure GPIO pins : SAI1_FSA_Pin SAI1_SDB_Pin SAI1_SCKA_Pin SAI1_SDA_Pin */
  GPIO_InitStruct.Pin = SAI1_FSA_Pin|SAI1_SDB_Pin|SAI1_SCKA_Pin|SAI1_SDA_Pin;
  GPIO_InitStruct.Mode = GPIO_MODE_AF_PP;
  GPIO_InitStruct.Pull = GPIO_NOPULL;
  GPIO_InitStruct.Speed = GPIO_SPEED_FREQ_LOW;
  GPIO_InitStruct.Alternate = GPIO_AF6_SAI1;
  HAL_GPIO_Init(GPIOE, &GPIO_InitStruct);

  /*Configure GPIO pin : QSPI_D2_Pin */
  GPIO_InitStruct.Pin = QSPI_D2_Pin;
  GPIO_InitStruct.Mode = GPIO_MODE_AF_PP;
  GPIO_InitStruct.Pull = GPIO_NOPULL;
  GPIO_InitStruct.Speed = GPIO_SPEED_FREQ_VERY_HIGH;
  GPIO_InitStruct.Alternate = GPIO_AF9_QUADSPI;
  HAL_GPIO_Init(QSPI_D2_GPIO_Port, &GPIO_InitStruct);

  /*Configure GPIO pins : RMII_TXD1_Pin RMII_TXD0_Pin RMII_TX_EN_Pin */
  GPIO_InitStruct.Pin = RMII_TXD1_Pin|RMII_TXD0_Pin|RMII_TX_EN_Pin;
  GPIO_InitStruct.Mode = GPIO_MODE_AF_PP;
  GPIO_InitStruct.Pull = GPIO_NOPULL;
  GPIO_InitStruct.Speed = GPIO_SPEED_FREQ_VERY_HIGH;
  GPIO_InitStruct.Alternate = GPIO_AF11_ETH;
  HAL_GPIO_Init(GPIOG, &GPIO_InitStruct);

  /*Configure GPIO pins : ARDUINO_SCL_D15_Pin ARDUINO_SDA_D14_Pin */
  GPIO_InitStruct.Pin = ARDUINO_SCL_D15_Pin|ARDUINO_SDA_D14_Pin;
  GPIO_InitStruct.Mode = GPIO_MODE_AF_OD;
  GPIO_InitStruct.Pull = GPIO_PULLUP;
  GPIO_InitStruct.Speed = GPIO_SPEED_FREQ_LOW;
  GPIO_InitStruct.Alternate = GPIO_AF4_I2C1;
  HAL_GPIO_Init(GPIOB, &GPIO_InitStruct);

  /*Configure GPIO pins : ULPI_D7_Pin ULPI_D6_Pin ULPI_D5_Pin ULPI_D3_Pin
                           ULPI_D2_Pin ULPI_D1_Pin ULPI_D4_Pin */
  GPIO_InitStruct.Pin = ULPI_D7_Pin|ULPI_D6_Pin|ULPI_D5_Pin|ULPI_D3_Pin
                          |ULPI_D2_Pin|ULPI_D1_Pin|ULPI_D4_Pin;
  GPIO_InitStruct.Mode = GPIO_MODE_AF_PP;
  GPIO_InitStruct.Pull = GPIO_NOPULL;
  GPIO_InitStruct.Speed = GPIO_SPEED_FREQ_VERY_HIGH;
  GPIO_InitStruct.Alternate = GPIO_AF10_OTG_HS;
  HAL_GPIO_Init(GPIOB, &GPIO_InitStruct);

  /*Configure GPIO pins : uSD_D3_Pin uSD_D2_Pin */
  GPIO_InitStruct.Pin = uSD_D3_Pin|uSD_D2_Pin;
  GPIO_InitStruct.Mode = GPIO_MODE_AF_PP;
  GPIO_InitStruct.Pull = GPIO_NOPULL;
  GPIO_InitStruct.Speed = GPIO_SPEED_FREQ_VERY_HIGH;
  GPIO_InitStruct.Alternate = GPIO_AF10_SDMMC2;
  HAL_GPIO_Init(GPIOB, &GPIO_InitStruct);

  /*Configure GPIO pins : uSD_CMD_Pin uSD_CLK_Pin */
  GPIO_InitStruct.Pin = uSD_CMD_Pin|uSD_CLK_Pin;
  GPIO_InitStruct.Mode = GPIO_MODE_AF_PP;
  GPIO_InitStruct.Pull = GPIO_NOPULL;
  GPIO_InitStruct.Speed = GPIO_SPEED_FREQ_VERY_HIGH;
  GPIO_InitStruct.Alternate = GPIO_AF11_SDMMC2;
  HAL_GPIO_Init(GPIOD, &GPIO_InitStruct);

  /*Configure GPIO pin : WIFI_RX_Pin */
  GPIO_InitStruct.Pin = WIFI_RX_Pin;
  GPIO_InitStruct.Mode = GPIO_MODE_AF_PP;
  GPIO_InitStruct.Pull = GPIO_NOPULL;
  GPIO_InitStruct.Speed = GPIO_SPEED_FREQ_VERY_HIGH;
  GPIO_InitStruct.Alternate = GPIO_AF8_UART5;
  HAL_GPIO_Init(WIFI_RX_GPIO_Port, &GPIO_InitStruct);

  /*Configure GPIO pin : AUDIO_SDA_Pin */
  GPIO_InitStruct.Pin = AUDIO_SDA_Pin;
  GPIO_InitStruct.Mode = GPIO_MODE_AF_OD;
  GPIO_InitStruct.Pull = GPIO_PULLUP;
  GPIO_InitStruct.Speed = GPIO_SPEED_FREQ_VERY_HIGH;
  GPIO_InitStruct.Alternate = GPIO_AF11_I2C4;
  HAL_GPIO_Init(AUDIO_SDA_GPIO_Port, &GPIO_InitStruct);

  /*Configure GPIO pin : QSPI_NCS_Pin */
  GPIO_InitStruct.Pin = QSPI_NCS_Pin;
  GPIO_InitStruct.Mode = GPIO_MODE_AF_PP;
  GPIO_InitStruct.Pull = GPIO_NOPULL;
  GPIO_InitStruct.Speed = GPIO_SPEED_FREQ_VERY_HIGH;
  GPIO_InitStruct.Alternate = GPIO_AF10_QUADSPI;
  HAL_GPIO_Init(QSPI_NCS_GPIO_Port, &GPIO_InitStruct);

  /*Configure GPIO pins : LD_USER1_Pin Audio_INT_Pin WIFI_RST_Pin ARD_D8_Pin
                           LD_USER2_Pin ARD_D7_Pin ARD_D4_Pin ARD_D2_Pin */
  GPIO_InitStruct.Pin = LD_USER1_Pin|Audio_INT_Pin|WIFI_RST_Pin|ARD_D8_Pin
                          |LD_USER2_Pin|ARD_D7_Pin|ARD_D4_Pin|ARD_D2_Pin;
  GPIO_InitStruct.Mode = GPIO_MODE_INPUT;
  GPIO_InitStruct.Pull = GPIO_NOPULL;
  HAL_GPIO_Init(GPIOJ, &GPIO_InitStruct);

  /*Configure GPIO pins : DFSDM_DATIN5_Pin DFSDM_DATIN1_Pin */
  GPIO_InitStruct.Pin = DFSDM_DATIN5_Pin|DFSDM_DATIN1_Pin;
  GPIO_InitStruct.Mode = GPIO_MODE_AF_PP;
  GPIO_InitStruct.Pull = GPIO_NOPULL;
  GPIO_InitStruct.Speed = GPIO_SPEED_FREQ_LOW;
  GPIO_InitStruct.Alternate = GPIO_AF3_DFSDM1;
  HAL_GPIO_Init(GPIOC, &GPIO_InitStruct);

  /*Configure GPIO pins : QSPI_D1_Pin QSPI_D0_Pin */
  GPIO_InitStruct.Pin = QSPI_D1_Pin|QSPI_D0_Pin;
  GPIO_InitStruct.Mode = GPIO_MODE_AF_PP;
  GPIO_InitStruct.Pull = GPIO_NOPULL;
  GPIO_InitStruct.Speed = GPIO_SPEED_FREQ_VERY_HIGH;
  GPIO_InitStruct.Alternate = GPIO_AF9_QUADSPI;
  HAL_GPIO_Init(GPIOC, &GPIO_InitStruct);

  /*Configure GPIO pin : ARD_D13_SCK_Pin */
  GPIO_InitStruct.Pin = ARD_D13_SCK_Pin;
  GPIO_InitStruct.Mode = GPIO_MODE_AF_PP;
  GPIO_InitStruct.Pull = GPIO_NOPULL;
  GPIO_InitStruct.Speed = GPIO_SPEED_FREQ_LOW;
  GPIO_InitStruct.Alternate = GPIO_AF5_SPI2;
  HAL_GPIO_Init(ARD_D13_SCK_GPIO_Port, &GPIO_InitStruct);

  /*Configure GPIO pins : NC4_Pin NC5_Pin uSD_Detect_Pin */
  GPIO_InitStruct.Pin = NC4_Pin|NC5_Pin|uSD_Detect_Pin;
  GPIO_InitStruct.Mode = GPIO_MODE_INPUT;
  GPIO_InitStruct.Pull = GPIO_NOPULL;
  HAL_GPIO_Init(GPIOI, &GPIO_InitStruct);

  /*Configure GPIO pins : NC3_Pin NC2_Pin NC1_Pin NC8_Pin
                           NC7_Pin */
  GPIO_InitStruct.Pin = NC3_Pin|NC2_Pin|NC1_Pin|NC8_Pin
                          |NC7_Pin;
  GPIO_InitStruct.Mode = GPIO_MODE_INPUT;
  GPIO_InitStruct.Pull = GPIO_NOPULL;
  HAL_GPIO_Init(GPIOK, &GPIO_InitStruct);

  /*Configure GPIO pin : SPDIF_RX_Pin */
  GPIO_InitStruct.Pin = SPDIF_RX_Pin;
  GPIO_InitStruct.Mode = GPIO_MODE_AF_PP;
  GPIO_InitStruct.Pull = GPIO_NOPULL;
  GPIO_InitStruct.Speed = GPIO_SPEED_FREQ_LOW;
  GPIO_InitStruct.Alternate = GPIO_AF7_SPDIFRX;
  HAL_GPIO_Init(SPDIF_RX_GPIO_Port, &GPIO_InitStruct);

  /*Configure GPIO pins : uSD_D1_Pin uSD_D0_Pin */
  GPIO_InitStruct.Pin = uSD_D1_Pin|uSD_D0_Pin;
  GPIO_InitStruct.Mode = GPIO_MODE_AF_PP;
  GPIO_InitStruct.Pull = GPIO_NOPULL;
  GPIO_InitStruct.Speed = GPIO_SPEED_FREQ_VERY_HIGH;
  GPIO_InitStruct.Alternate = GPIO_AF11_SDMMC2;
  HAL_GPIO_Init(GPIOG, &GPIO_InitStruct);

  /*Configure GPIO pins : RMII_RXER_Pin OTG_FS_OverCurrent_Pin */
  GPIO_InitStruct.Pin = RMII_RXER_Pin|OTG_FS_OverCurrent_Pin;
  GPIO_InitStruct.Mode = GPIO_MODE_INPUT;
  GPIO_InitStruct.Pull = GPIO_NOPULL;
  HAL_GPIO_Init(GPIOD, &GPIO_InitStruct);

  /*Configure GPIO pin : DFSDM_CKOUT_Pin */
  GPIO_InitStruct.Pin = DFSDM_CKOUT_Pin;
  GPIO_InitStruct.Mode = GPIO_MODE_AF_PP;
  GPIO_InitStruct.Pull = GPIO_NOPULL;
  GPIO_InitStruct.Speed = GPIO_SPEED_FREQ_LOW;
  GPIO_InitStruct.Alternate = GPIO_AF3_DFSDM1;
  HAL_GPIO_Init(DFSDM_CKOUT_GPIO_Port, &GPIO_InitStruct);

  /*Configure GPIO pin : SPI2_NSS_Pin */
  GPIO_InitStruct.Pin = SPI2_NSS_Pin;
  GPIO_InitStruct.Mode = GPIO_MODE_AF_PP;
  GPIO_InitStruct.Pull = GPIO_NOPULL;
  GPIO_InitStruct.Speed = GPIO_SPEED_FREQ_VERY_HIGH;
  GPIO_InitStruct.Alternate = GPIO_AF5_SPI2;
  HAL_GPIO_Init(SPI2_NSS_GPIO_Port, &GPIO_InitStruct);

  /*Configure GPIO pin : WIFI_TX_Pin */
  GPIO_InitStruct.Pin = WIFI_TX_Pin;
  GPIO_InitStruct.Mode = GPIO_MODE_AF_PP;
  GPIO_InitStruct.Pull = GPIO_NOPULL;
  GPIO_InitStruct.Speed = GPIO_SPEED_FREQ_VERY_HIGH;
  GPIO_InitStruct.Alternate = GPIO_AF8_UART5;
  HAL_GPIO_Init(WIFI_TX_GPIO_Port, &GPIO_InitStruct);

  /*Configure GPIO pin : VCP_RX_Pin */
  GPIO_InitStruct.Pin = VCP_RX_Pin;
  GPIO_InitStruct.Mode = GPIO_MODE_AF_PP;
  GPIO_InitStruct.Pull = GPIO_NOPULL;
  GPIO_InitStruct.Speed = GPIO_SPEED_FREQ_VERY_HIGH;
  GPIO_InitStruct.Alternate = GPIO_AF7_USART1;
  HAL_GPIO_Init(VCP_RX_GPIO_Port, &GPIO_InitStruct);

  /*Configure GPIO pin : VCP_TX_Pin */
  GPIO_InitStruct.Pin = VCP_TX_Pin;
  GPIO_InitStruct.Mode = GPIO_MODE_AF_PP;
  GPIO_InitStruct.Pull = GPIO_NOPULL;
  GPIO_InitStruct.Speed = GPIO_SPEED_FREQ_LOW;
  GPIO_InitStruct.Alternate = GPIO_AF7_USART1;
  HAL_GPIO_Init(VCP_TX_GPIO_Port, &GPIO_InitStruct);

  /*Configure GPIO pin : ULPI_DIR_Pin */
  GPIO_InitStruct.Pin = ULPI_DIR_Pin;
  GPIO_InitStruct.Mode = GPIO_MODE_AF_PP;
  GPIO_InitStruct.Pull = GPIO_NOPULL;
  GPIO_InitStruct.Speed = GPIO_SPEED_FREQ_VERY_HIGH;
  GPIO_InitStruct.Alternate = GPIO_AF10_OTG_HS;
  HAL_GPIO_Init(ULPI_DIR_GPIO_Port, &GPIO_InitStruct);

  /*Configure GPIO pin : ARD_D5_PWM_Pin */
  GPIO_InitStruct.Pin = ARD_D5_PWM_Pin;
  GPIO_InitStruct.Mode = GPIO_MODE_AF_PP;
  GPIO_InitStruct.Pull = GPIO_NOPULL;
  GPIO_InitStruct.Speed = GPIO_SPEED_FREQ_LOW;
  GPIO_InitStruct.Alternate = GPIO_AF2_TIM3;
  HAL_GPIO_Init(ARD_D5_PWM_GPIO_Port, &GPIO_InitStruct);

  /*Configure GPIO pins : ARD_D0_RX_Pin ARDUINO_TX_D1_Pin */
  GPIO_InitStruct.Pin = ARD_D0_RX_Pin|ARDUINO_TX_D1_Pin;
  GPIO_InitStruct.Mode = GPIO_MODE_AF_PP;
  GPIO_InitStruct.Pull = GPIO_NOPULL;
  GPIO_InitStruct.Speed = GPIO_SPEED_FREQ_VERY_HIGH;
  GPIO_InitStruct.Alternate = GPIO_AF8_USART6;
  HAL_GPIO_Init(GPIOC, &GPIO_InitStruct);

  /*Configure GPIO pin : ULPI_NXT_Pin */
  GPIO_InitStruct.Pin = ULPI_NXT_Pin;
  GPIO_InitStruct.Mode = GPIO_MODE_AF_PP;
  GPIO_InitStruct.Pull = GPIO_NOPULL;
  GPIO_InitStruct.Speed = GPIO_SPEED_FREQ_VERY_HIGH;
  GPIO_InitStruct.Alternate = GPIO_AF10_OTG_HS;
  HAL_GPIO_Init(ULPI_NXT_GPIO_Port, &GPIO_InitStruct);

  /*Configure GPIO pin : SAI1_MCLKA_Pin */
  GPIO_InitStruct.Pin = SAI1_MCLKA_Pin;
  GPIO_InitStruct.Mode = GPIO_MODE_AF_PP;
  GPIO_InitStruct.Pull = GPIO_NOPULL;
  GPIO_InitStruct.Speed = GPIO_SPEED_FREQ_LOW;
  GPIO_InitStruct.Alternate = GPIO_AF6_SAI1;
  HAL_GPIO_Init(SAI1_MCLKA_GPIO_Port, &GPIO_InitStruct);

  /*Configure GPIO pins : EXT_SDA_Pin EXT_SCL_Pin */
  GPIO_InitStruct.Pin = EXT_SDA_Pin|EXT_SCL_Pin;
  GPIO_InitStruct.Mode = GPIO_MODE_INPUT;
  GPIO_InitStruct.Pull = GPIO_NOPULL;
  HAL_GPIO_Init(GPIOG, &GPIO_InitStruct);

  /*Configure GPIO pin : ARD_D6_PWM_Pin */
  GPIO_InitStruct.Pin = ARD_D6_PWM_Pin;
  GPIO_InitStruct.Mode = GPIO_MODE_AF_PP;
  GPIO_InitStruct.Pull = GPIO_NOPULL;
  GPIO_InitStruct.Speed = GPIO_SPEED_FREQ_LOW;
  GPIO_InitStruct.Alternate = GPIO_AF3_TIM11;
  HAL_GPIO_Init(ARD_D6_PWM_GPIO_Port, &GPIO_InitStruct);

  /*Configure GPIO pin : ARD_D3_PWM_Pin */
  GPIO_InitStruct.Pin = ARD_D3_PWM_Pin;
  GPIO_InitStruct.Mode = GPIO_MODE_AF_PP;
  GPIO_InitStruct.Pull = GPIO_NOPULL;
  GPIO_InitStruct.Speed = GPIO_SPEED_FREQ_LOW;
  GPIO_InitStruct.Alternate = GPIO_AF3_TIM10;
  HAL_GPIO_Init(ARD_D3_PWM_GPIO_Port, &GPIO_InitStruct);

  /*Configure GPIO pins : ARDUINO_A1_Pin ARDUINO_A2_Pin ARDUINO_A3_Pin */
  GPIO_InitStruct.Pin = ARDUINO_A1_Pin|ARDUINO_A2_Pin|ARDUINO_A3_Pin;
  GPIO_InitStruct.Mode = GPIO_MODE_ANALOG;
  GPIO_InitStruct.Pull = GPIO_NOPULL;
  HAL_GPIO_Init(GPIOF, &GPIO_InitStruct);

  /*Configure GPIO pin : ULPI_STP_Pin */
  GPIO_InitStruct.Pin = ULPI_STP_Pin;
  GPIO_InitStruct.Mode = GPIO_MODE_AF_PP;
  GPIO_InitStruct.Pull = GPIO_NOPULL;
  GPIO_InitStruct.Speed = GPIO_SPEED_FREQ_VERY_HIGH;
  GPIO_InitStruct.Alternate = GPIO_AF10_OTG_HS;
  HAL_GPIO_Init(ULPI_STP_GPIO_Port, &GPIO_InitStruct);

  /*Configure GPIO pins : RMII_MDC_Pin RMII_RXD0_Pin RMII_RXD1_Pin */
  GPIO_InitStruct.Pin = RMII_MDC_Pin|RMII_RXD0_Pin|RMII_RXD1_Pin;
  GPIO_InitStruct.Mode = GPIO_MODE_AF_PP;
  GPIO_InitStruct.Pull = GPIO_NOPULL;
  GPIO_InitStruct.Speed = GPIO_SPEED_FREQ_VERY_HIGH;
  GPIO_InitStruct.Alternate = GPIO_AF11_ETH;
  HAL_GPIO_Init(GPIOC, &GPIO_InitStruct);

  /*Configure GPIO pin : ARD_A2_Pin */
  GPIO_InitStruct.Pin = ARD_A2_Pin;
  GPIO_InitStruct.Mode = GPIO_MODE_ANALOG;
  GPIO_InitStruct.Pull = GPIO_NOPULL;
  HAL_GPIO_Init(ARD_A2_GPIO_Port, &GPIO_InitStruct);

  /*Configure GPIO pin : QSPI_CLK_Pin */
  GPIO_InitStruct.Pin = QSPI_CLK_Pin;
  GPIO_InitStruct.Mode = GPIO_MODE_AF_PP;
  GPIO_InitStruct.Pull = GPIO_NOPULL;
  GPIO_InitStruct.Speed = GPIO_SPEED_FREQ_VERY_HIGH;
  GPIO_InitStruct.Alternate = GPIO_AF9_QUADSPI;
  HAL_GPIO_Init(QSPI_CLK_GPIO_Port, &GPIO_InitStruct);

  /*Configure GPIO pin : AUDIO_SCL_Pin */
  GPIO_InitStruct.Pin = AUDIO_SCL_Pin;
  GPIO_InitStruct.Mode = GPIO_MODE_AF_OD;
  GPIO_InitStruct.Pull = GPIO_PULLUP;
  GPIO_InitStruct.Speed = GPIO_SPEED_FREQ_VERY_HIGH;
  GPIO_InitStruct.Alternate = GPIO_AF4_I2C4;
  HAL_GPIO_Init(AUDIO_SCL_GPIO_Port, &GPIO_InitStruct);

  /*Configure GPIO pin : QSPI_D3_Pin */
  GPIO_InitStruct.Pin = QSPI_D3_Pin;
  GPIO_InitStruct.Mode = GPIO_MODE_AF_PP;
  GPIO_InitStruct.Pull = GPIO_NOPULL;
  GPIO_InitStruct.Speed = GPIO_SPEED_FREQ_VERY_HIGH;
  GPIO_InitStruct.Alternate = GPIO_AF9_QUADSPI;
  HAL_GPIO_Init(QSPI_D3_GPIO_Port, &GPIO_InitStruct);

  /*Configure GPIO pins : RMII_REF_CLK_Pin RMII_MDIO_Pin RMII_CRS_DV_Pin */
  GPIO_InitStruct.Pin = RMII_REF_CLK_Pin|RMII_MDIO_Pin|RMII_CRS_DV_Pin;
  GPIO_InitStruct.Mode = GPIO_MODE_AF_PP;
  GPIO_InitStruct.Pull = GPIO_NOPULL;
  GPIO_InitStruct.Speed = GPIO_SPEED_FREQ_VERY_HIGH;
  GPIO_InitStruct.Alternate = GPIO_AF11_ETH;
  HAL_GPIO_Init(GPIOA, &GPIO_InitStruct);

  /*Configure GPIO pin : B_USER_Pin */
  GPIO_InitStruct.Pin = B_USER_Pin;
  GPIO_InitStruct.Mode = GPIO_MODE_IT_RISING;
  GPIO_InitStruct.Pull = GPIO_NOPULL;
  HAL_GPIO_Init(B_USER_GPIO_Port, &GPIO_InitStruct);

  /*Configure GPIO pin : SPDIF_TX_Pin */
  GPIO_InitStruct.Pin = SPDIF_TX_Pin;
  GPIO_InitStruct.Mode = GPIO_MODE_AF_PP;
  GPIO_InitStruct.Pull = GPIO_NOPULL;
  GPIO_InitStruct.Speed = GPIO_SPEED_FREQ_LOW;
  GPIO_InitStruct.Alternate = GPIO_AF10_SAI2;
  HAL_GPIO_Init(SPDIF_TX_GPIO_Port, &GPIO_InitStruct);

  /*Configure GPIO pin : EXT_RST_Pin */
  GPIO_InitStruct.Pin = EXT_RST_Pin;
  GPIO_InitStruct.Mode = GPIO_MODE_INPUT;
  GPIO_InitStruct.Pull = GPIO_NOPULL;
  HAL_GPIO_Init(EXT_RST_GPIO_Port, &GPIO_InitStruct);

  /*Configure GPIO pin : ARD_A0_Pin */
  GPIO_InitStruct.Pin = ARD_A0_Pin;
  GPIO_InitStruct.Mode = GPIO_MODE_ANALOG;
  GPIO_InitStruct.Pull = GPIO_NOPULL;
  HAL_GPIO_Init(ARD_A0_GPIO_Port, &GPIO_InitStruct);

  /*Configure GPIO pins : ULPI_CLK_Pin ULPI_D0_Pin */
  GPIO_InitStruct.Pin = ULPI_CLK_Pin|ULPI_D0_Pin;
  GPIO_InitStruct.Mode = GPIO_MODE_AF_PP;
  GPIO_InitStruct.Pull = GPIO_NOPULL;
  GPIO_InitStruct.Speed = GPIO_SPEED_FREQ_VERY_HIGH;
  GPIO_InitStruct.Alternate = GPIO_AF10_OTG_HS;
  HAL_GPIO_Init(GPIOA, &GPIO_InitStruct);

  /*Configure GPIO pin : ARDUINO_PWM_D6_Pin */
  GPIO_InitStruct.Pin = ARDUINO_PWM_D6_Pin;
  GPIO_InitStruct.Mode = GPIO_MODE_AF_PP;
  GPIO_InitStruct.Pull = GPIO_NOPULL;
  GPIO_InitStruct.Speed = GPIO_SPEED_FREQ_LOW;
  GPIO_InitStruct.Alternate = GPIO_AF9_TIM12;
  HAL_GPIO_Init(ARDUINO_PWM_D6_GPIO_Port, &GPIO_InitStruct);

  /*Configure GPIO pins : ARDUINO_MISO_D12_Pin ARDUINO_MOSI_PWM_D11_Pin */
  GPIO_InitStruct.Pin = ARDUINO_MISO_D12_Pin|ARDUINO_MOSI_PWM_D11_Pin;
  GPIO_InitStruct.Mode = GPIO_MODE_AF_PP;
  GPIO_InitStruct.Pull = GPIO_NOPULL;
  GPIO_InitStruct.Speed = GPIO_SPEED_FREQ_LOW;
  GPIO_InitStruct.Alternate = GPIO_AF5_SPI2;
  HAL_GPIO_Init(GPIOB, &GPIO_InitStruct);

}

void Error_Handler(void)
{
  while(1)
  {
  }
}

/************************ (C) COPYRIGHT STMicroelectronics *****END OF FILE****/
